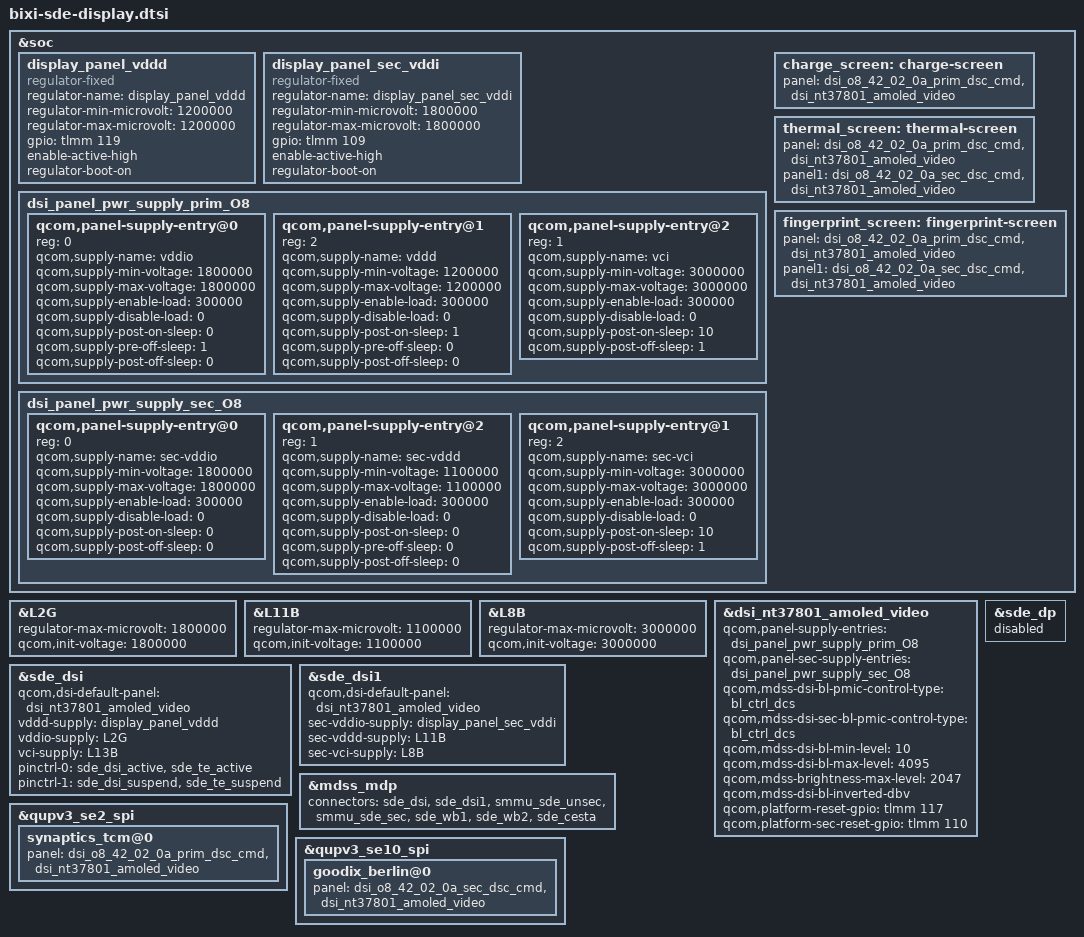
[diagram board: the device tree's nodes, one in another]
#include "sun-sde-display.dtsi"
#include "dsi-panel-o8-42-02-0a-prim-dsc-cmd.dtsi"
#include "dsi-panel-o8-42-02-0a-sec-dsc-cmd.dtsi"
#include "dsi-panel-nt37801-dsc-wqhd-plus-video.dtsi"


&soc {
    	display_panel_vddd: display_panel_vddd {
		compatible = "regulator-fixed";
		regulator-name = "display_panel_vddd";
		regulator-min-microvolt = <1200000>;
		regulator-max-microvolt = <1200000>;
		gpio = <&tlmm 119 0>;
		enable-active-high;
		regulator-boot-on;
    };

    	display_panel_sec_vddi: display_panel_sec_vddi {
		compatible = "regulator-fixed";
		regulator-name = "display_panel_sec_vddi";
		regulator-min-microvolt = <1800000>;
		regulator-max-microvolt = <1800000>;
		gpio = <&tlmm 109 0>;
		enable-active-high;
		regulator-boot-on;
    };

	dsi_panel_pwr_supply_prim_O8: dsi_panel_pwr_supply_prim_O8 {
		qcom,panel-supply-entry@0 {
			reg = <0>;
			qcom,supply-name = "vddio";
			qcom,supply-min-voltage = <1800000>;
			qcom,supply-max-voltage = <1800000>;
			qcom,supply-enable-load = <300000>;
			qcom,supply-disable-load = <0>;
			qcom,supply-post-on-sleep = <0>;
			qcom,supply-pre-off-sleep = <1>;
			qcom,supply-post-off-sleep = <0>;
		};
		qcom,panel-supply-entry@1 {
			reg = <2>;
			qcom,supply-name = "vddd";
			qcom,supply-min-voltage = <1200000>;
			qcom,supply-max-voltage = <1200000>;
			qcom,supply-enable-load = <300000>;
			qcom,supply-disable-load = <0>;
			qcom,supply-post-on-sleep = <1>;
			qcom,supply-pre-off-sleep = <0>;
			qcom,supply-post-off-sleep = <0>;
		};
		qcom,panel-supply-entry@2 {
			reg = <1>;
			qcom,supply-name = "vci";
			qcom,supply-min-voltage = <3000000>;
			qcom,supply-max-voltage = <3000000>;
			qcom,supply-enable-load = <300000>;
			qcom,supply-disable-load = <0>;
			qcom,supply-post-on-sleep = <10>;
			qcom,supply-post-off-sleep = <1>;
		};
	};

	dsi_panel_pwr_supply_sec_O8: dsi_panel_pwr_supply_sec_O8 {
		qcom,panel-supply-entry@0 {
			reg = <0>;
			qcom,supply-name = "sec-vddio";
			qcom,supply-min-voltage = <1800000>;
			qcom,supply-max-voltage = <1800000>;
			qcom,supply-enable-load = <300000>;
			qcom,supply-disable-load = <0>;
			qcom,supply-post-on-sleep = <0>;
			qcom,supply-post-off-sleep = <0>;
		};
		qcom,panel-supply-entry@2 {
			reg = <1>;
			qcom,supply-name = "sec-vddd";
			qcom,supply-min-voltage = <1100000>;
			qcom,supply-max-voltage = <1100000>;
			qcom,supply-enable-load = <300000>;
			qcom,supply-disable-load = <0>;
			qcom,supply-post-on-sleep = <0>;
			qcom,supply-pre-off-sleep = <0>;
			qcom,supply-post-off-sleep = <0>;
		};
		qcom,panel-supply-entry@1 {
			reg = <2>;
			qcom,supply-name = "sec-vci";
			qcom,supply-min-voltage = <3000000>;
			qcom,supply-max-voltage = <3000000>;
			qcom,supply-enable-load = <300000>;
			qcom,supply-disable-load = <0>;
			qcom,supply-post-on-sleep = <10>;
			qcom,supply-post-off-sleep = <1>;
		};
	};
};

&L2G {
		regulator-max-microvolt = <1800000>;
		qcom,init-voltage = <1800000>;
};

&L11B {
		regulator-max-microvolt = <1100000>;
		qcom,init-voltage = <1100000>;
};

&L8B {
		regulator-max-microvolt = <3000000>;
		qcom,init-voltage = <3000000>;
};

&dsi_nt37801_amoled_video {
	qcom,panel-supply-entries = <&dsi_panel_pwr_supply_prim_O8>;
	qcom,panel-sec-supply-entries = <&dsi_panel_pwr_supply_sec_O8>;
	qcom,mdss-dsi-bl-pmic-control-type = "bl_ctrl_dcs";
	qcom,mdss-dsi-sec-bl-pmic-control-type = "bl_ctrl_dcs";
	qcom,mdss-dsi-bl-min-level = <10>;
	qcom,mdss-dsi-bl-max-level = <4095>;
	qcom,mdss-brightness-max-level = <2047>;
	qcom,mdss-dsi-bl-inverted-dbv;
	qcom,platform-reset-gpio = <&tlmm 117 0>;
	qcom,platform-sec-reset-gpio = <&tlmm 110 0>;
};

&sde_dsi {
	qcom,dsi-default-panel = <&dsi_nt37801_amoled_video>;
	vddd-supply = <&display_panel_vddd>;
	vddio-supply = <&L2G>;
	vci-supply = <&L13B>;
	pinctrl-names = "panel_active", "panel_suspend";
	pinctrl-0 = <&sde_dsi_active &sde_te_active>;
	pinctrl-1 = <&sde_dsi_suspend &sde_te_suspend>;
};

&sde_dsi1 {
	qcom,dsi-default-panel = <&dsi_nt37801_amoled_video>;
	sec-vddio-supply = <&display_panel_sec_vddi>;
	sec-vddd-supply = <&L11B>;
	sec-vci-supply = <&L8B>;
};

&mdss_mdp {
	connectors = <&sde_dsi &sde_dsi1 &smmu_sde_unsec &smmu_sde_sec &sde_wb1 &sde_wb2 &sde_cesta>;
};

&sde_dp {
	status = "disabled";
};

&qupv3_se2_spi {
	synaptics_tcm@0 {
		panel = <&dsi_o8_42_02_0a_prim_dsc_cmd
			&dsi_nt37801_amoled_video>;
	};
};

&qupv3_se10_spi {
	goodix_berlin@0 {
		panel = <&dsi_o8_42_02_0a_sec_dsc_cmd
			&dsi_nt37801_amoled_video>;
	};
};

&soc {
	charge_screen: charge-screen {
		panel  = <&dsi_o8_42_02_0a_prim_dsc_cmd
			&dsi_nt37801_amoled_video>;
	};
};

&soc {
	thermal_screen: thermal-screen {
		panel = <&dsi_o8_42_02_0a_prim_dsc_cmd
			&dsi_nt37801_amoled_video>;
		panel1 = <&dsi_o8_42_02_0a_sec_dsc_cmd
			&dsi_nt37801_amoled_video>;
	};
	fingerprint_screen: fingerprint-screen {
		panel = <&dsi_o8_42_02_0a_prim_dsc_cmd
			&dsi_nt37801_amoled_video>;
		panel1 = <&dsi_o8_42_02_0a_sec_dsc_cmd
			&dsi_nt37801_amoled_video>;
	};
};
